# filter_ctrl_wrap: IP-XACT component
VLNV tenstorrent.com:ocah:filter_ctrl_wrap:1.0

## Address spaces and blocks
filter_ctrl_wrap_mmap.filter_ctrl_wrap: base 'h0, range 'h200, width 64

## Registers
Registers are 64-bit, read-write, reset 0x3000 unless marked. A register's access mark holds for its fields unless they carry their own. Offsets are from the block's base; lines under a group give offsets from that group; [hi:lo] are bit positions; {n}, {i} and the like mark numbered series; 'fields as' and 'values as' point back to an identical list; <NAME> marks a mode.

## filter_ctrl_wrap_mmap.filter_ctrl_wrap — Wrapper address map instantiating one filter control register block per filter entry.
Base 0x00000000
{0x0+0x20*i} filter_ctrl[{i}] (i=0..15) group — Per-filter access-control registers defining permitted address ranges and transaction attributes.
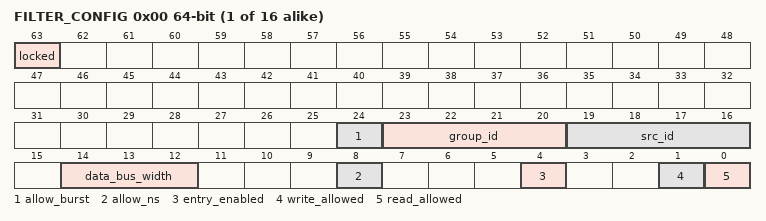
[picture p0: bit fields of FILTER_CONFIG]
  0x00 FILTER_CONFIG access per field
    [63] locked rw write-1-sets — Lock filter configurations. Write once register. Once set, this bit cannot be cleared, and every subsequent write to this filter entry's FILTER_CONFIG, START_ADDR and END_ADDR registers terminates with SLVERR and leaves the register unchanged; reads still return the locked configuration.
    [24] allow_burst rw — Filter entry will match if this field is 1 or if this field is 0 and the burst len AxLEN is 0. This field also selects the granule of the address range: 4KB when it is 1, 2^data_bus_width bytes when it is 0. See start_addr and end_addr for how the range is widened to that granule.
    [23:20] group_id rw — Group ID field to match. Filter entry will match if the transactions group_id matches the value in this field. Note the corner case is the opposite of src_id: the bypass keys off the transaction, not this field. A transaction whose group_id is 0 matches regardless of this field, and a value of 0 here is not a wildcard. Unused for SEP/SMC, where group_id filtering is disabled at build time and this field has no effect
    [19:16] src_id rw — Source ID field to match. Filter entry will match if the transactions src_id matches the value in this field. A value of 0 in this field is a wildcard: src_id matching is bypassed and the entry matches any src_id. Consequently there is no way to match only transactions whose src_id is 0.
    [14:12] data_bus_width ro — Data bus width in bytes, encoded as 2^value: log2 of the instance's AXI data width in bytes, 3 for a 64-bit bus. The register has no storage, and the reset value is the 64-bit case.
    [8] allow_ns rw — Secure and Non-secure is categorized as AxPROT[1] in the AXI protocol, where AxPROT[1] == 0 means secure and AxPROT[1] == 1 means Non-secure. Filter entry will match if AxPROT[1] matches the value in this field
    [4] entry_enabled rw — Filter entry enabled. A = 0 means this entry is disabled, A = 1 means this entry is enabled and will be used to filter
    [1] write_allowed rw — Upon match of transaction to filter fields, whether the transaction has write permissions
    [0] read_allowed rw — Upon match of transaction to filter fields, whether the transaction has read permissions
  0x08 START_ADDR reset 0x0
    [55:0] start_addr — Start of the allowable address range, rounded down to the base of its granule. The granule is 4KB when allow_burst is 1, and 2^data_bus_width bytes when allow_burst is 0. Address matching ignores the address bits below the granule, so the accepted range always spans whole granules and is never narrower than one: a range shorter than the granule, start_addr == end_addr included, still admits the whole granule, and two granules if it straddles a granule boundary. Hardware writes the rounded start_addr and end_addr back into these fields only when both land in the same granule; otherwise readback returns the programmed values even though matching is still granule-aligned.
  0x10 END_ADDR reset 0x7
    [55:0] end_addr — End of the allowable address range, rounded up to the top of its granule. The granule and the write-back behaviour are described under start_addr. Resets to 7, the top of the first 8-byte granule that applies while bursts are disabled on a 64-bit bus; the reset does not follow the data width.

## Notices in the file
SPDX-License-Identifier: Apache-2.0
SPDX-FileCopyrightText: 2026 Tenstorrent USA, Inc.
